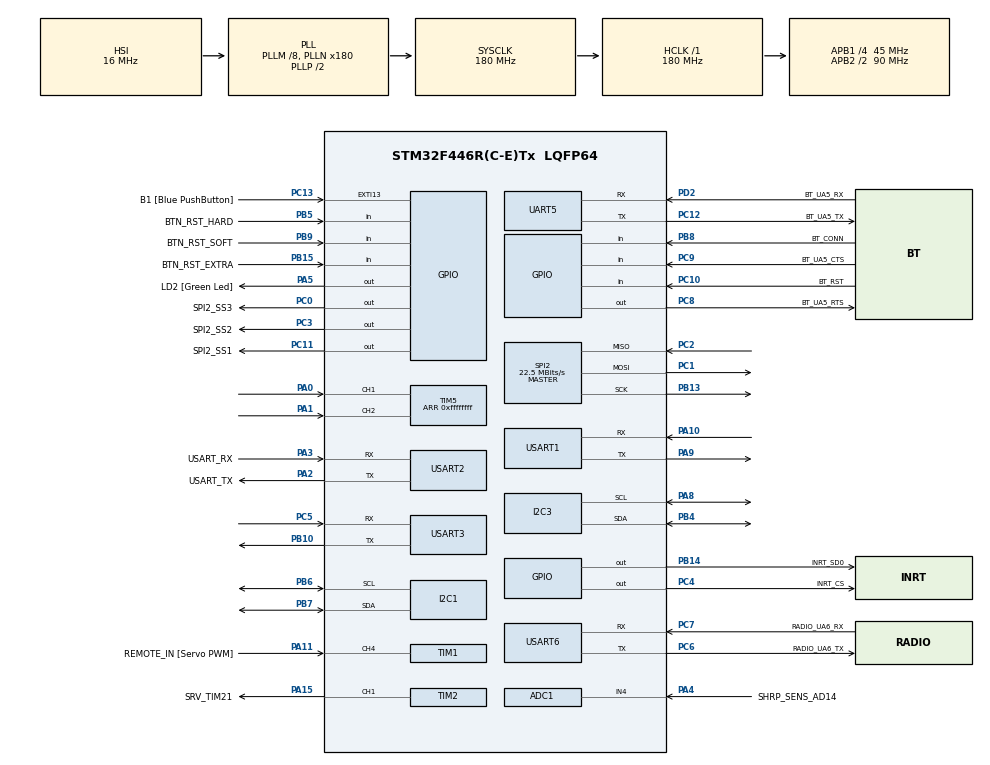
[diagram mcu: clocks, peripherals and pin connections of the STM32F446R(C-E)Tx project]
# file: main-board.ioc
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ADC1.Channel-4\#ChannelRegularConversion=ADC_CHANNEL_4
ADC1.NbrOfConversionFlag=1
ADC1.Rank-4\#ChannelRegularConversion=1
ADC1.SamplingTime-4\#ChannelRegularConversion=ADC_SAMPLETIME_3CYCLES
ADC1.master=1
FREERTOS.INCLUDE_uxTaskGetStackHighWaterMark=1
FREERTOS.Tasks01=defaultTask,0,128,StartDefaultTask,Default,NULL
FREERTOS.configCHECK_FOR_STACK_OVERFLOW=2
FREERTOS.configGENERATE_RUN_TIME_STATS=1
Mcu.Family=STM32F4
Mcu.Name=STM32F446R(C-E)Tx
Mcu.Package=LQFP64
NVIC.ADC_IRQn=true\:5\:0\:false\:false\:true\:true\:true
NVIC.I2C1_EV_IRQn=true\:5\:0\:false\:false\:true\:true\:true
NVIC.I2C3_EV_IRQn=true\:5\:0\:false\:false\:true\:true\:true
NVIC.PriorityGroup=NVIC_PRIORITYGROUP_4
NVIC.TIM1_CC_IRQn=true\:5\:0\:false\:false\:true\:true\:true
NVIC.TIM4_IRQn=true\:5\:0\:false\:false\:true\:true\:true
NVIC.TIM8_TRG_COM_TIM14_IRQn=true\:0\:0\:false\:false\:true\:false\:false
NVIC.TimeBase=TIM8_TRG_COM_TIM14_IRQn
NVIC.TimeBaseIP=TIM14
PA0-WKUP.Signal=S_TIM5_CH1
PA1.Signal=S_TIM5_CH2
PA10.Mode=Asynchronous
PA10.Signal=USART1_RX
PA11.GPIO_Label=REMOTE_IN [Servo PWM]
PA11.Signal=S_TIM1_CH4
PA13.GPIO_Label=TMS
PA13.Signal=SYS_JTMS-SWDIO
PA14.GPIO_Label=TCK
PA14.Signal=SYS_JTCK-SWCLK
PA15.GPIO_Label=SRV_TIM21
PA15.Signal=S_TIM2_CH1_ETR
PA2.GPIO_Label=USART_TX
PA2.Mode=Asynchronous
PA2.Signal=USART2_TX
PA3.GPIO_Label=USART_RX
PA3.Mode=Asynchronous
PA3.Signal=USART2_RX
PA4.GPIO_Label=SHRP_SENS_AD14
PA4.Signal=ADCx_IN4
PA5.GPIO_Label=LD2 [Green Led]
PA5.Signal=GPIO_Output
PA8.Mode=I2C
PA8.Signal=I2C3_SCL
PA9.Mode=Asynchronous
PA9.Signal=USART1_TX
PB10.Mode=Asynchronous
PB10.Signal=USART3_TX
PB13.Mode=Full_Duplex_Master
PB13.Signal=SPI2_SCK
PB14.GPIO_Label=INRT_SD0
PB14.Signal=GPIO_Output
PB15.GPIO_Label=BTN_RST_EXTRA
PB15.GPIO_PuPd=GPIO_PULLUP
PB15.Signal=GPIO_Input
PB3.GPIO_Label=SWO
PB3.Signal=SYS_JTDO-SWO
PB4.Mode=I2C
PB4.Signal=I2C3_SDA
PB5.GPIO_Label=BTN_RST_HARD
PB5.GPIO_PuPd=GPIO_PULLUP
PB5.Signal=GPIO_Input
PB6.Mode=I2C
PB6.Signal=I2C1_SCL
PB7.Mode=I2C
PB7.Signal=I2C1_SDA
PB8.GPIO_Label=BT_CONN
PB8.Signal=GPIO_Input
PB9.GPIO_Label=BTN_RST_SOFT
PB9.GPIO_PuPd=GPIO_PULLUP
PB9.Signal=GPIO_Input
PC0.GPIO_Label=SPI2_SS3
PC0.Signal=GPIO_Output
PC1.Mode=Full_Duplex_Master
PC1.Signal=SPI2_MOSI
PC10.GPIO_Label=BT_RST
PC10.Signal=GPIO_Input
PC11.GPIO_Label=SPI2_SS1
PC11.Signal=GPIO_Output
PC12.GPIO_Label=BT_UA5_TX
PC12.Mode=Asynchronous
PC12.Signal=UART5_TX
PC13.GPIO_Label=B1 [Blue PushButton]
PC13.GPIO_ModeDefaultEXTI=GPIO_MODE_IT_FALLING
PC13.Signal=GPXTI13
PC14-OSC32_IN.Signal=RCC_OSC32_IN
PC15-OSC32_OUT.Signal=RCC_OSC32_OUT
PC2.Mode=Full_Duplex_Master
PC2.Signal=SPI2_MISO
PC3.GPIO_Label=SPI2_SS2
PC3.Signal=GPIO_Output
PC4.GPIO_Label=INRT_CS
PC4.Signal=GPIO_Output
PC5.Mode=Asynchronous
PC5.Signal=USART3_RX
PC6.GPIO_Label=RADIO_UA6_TX
PC6.Mode=Asynchronous
PC6.Signal=USART6_TX
PC7.GPIO_Label=RADIO_UA6_RX
PC7.Mode=Asynchronous
PC7.Signal=USART6_RX
PC8.GPIO_Label=BT_UA5_RTS
PC8.Signal=GPIO_Output
PC9.GPIO_Label=BT_UA5_CTS
PC9.Signal=GPIO_Input
PD2.GPIO_Label=BT_UA5_RX
PD2.Mode=Asynchronous
PD2.Signal=UART5_RX
PH0-OSC_IN.Signal=RCC_OSC_IN
PH1-OSC_OUT.Signal=RCC_OSC_OUT
ProjectManager.HeapSize=0x200
ProjectManager.StackSize=0x400
ProjectManager.TargetToolchain=TrueSTUDIO
RCC.AHBFreq_Value=180000000
RCC.APB1CLKDivider=RCC_HCLK_DIV4
RCC.APB1Freq_Value=45000000
RCC.APB1TimFreq_Value=90000000
RCC.APB2CLKDivider=RCC_HCLK_DIV2
RCC.APB2Freq_Value=90000000
RCC.APB2TimFreq_Value=180000000
RCC.CortexFreq_Value=180000000
RCC.FLatency-AdvancedSettings=FLASH_LATENCY_5
RCC.HCLKFreq_Value=180000000
RCC.HSE_VALUE=8000000
RCC.HSI_VALUE=16000000
RCC.LSE_VALUE=32768
RCC.PLLM=8
RCC.PLLN=180
RCC.SYSCLKFreq_VALUE=180000000
RCC.SYSCLKSource=RCC_SYSCLKSOURCE_PLLCLK
RCC.USBFreq_Value=180000000
RCC.VCOOutputFreq_Value=360000000
SH.ADCx_IN4.0=ADC1_IN4,IN4
SH.S_TIM1_CH4.0=TIM1_CH4,Input_Capture4_from_TI4
SH.S_TIM2_CH1_ETR.0=TIM2_CH1,PWM Generation1 CH1
SH.S_TIM5_CH1.0=TIM5_CH1,Encoder_Interface
SH.S_TIM5_CH2.0=TIM5_CH2,Encoder_Interface
SPI2.BaudRatePrescaler=SPI_BAUDRATEPRESCALER_2
SPI2.CalculateBaudRate=22.5 MBits/s
SPI2.Direction=SPI_DIRECTION_2LINES
SPI2.Mode=SPI_MODE_MASTER
SPI2.VirtualType=VM_MASTER
TIM1.Channel-Input_Capture4_from_TI4=TIM_CHANNEL_4
TIM1.ICFilter_CH4=15
TIM1.ICPolarity_CH4=TIM_INPUTCHANNELPOLARITY_BOTHEDGE
TIM1.Period=0xffff
TIM1.Prescaler=90-1
TIM2.Channel-PWM\ Generation1\ CH1=TIM_CHANNEL_1
TIM2.CounterMode=TIM_COUNTERMODE_UP
TIM2.Period=0
TIM2.TIM_MasterOutputTrigger=TIM_TRGO_RESET
TIM4.Channel-Output\ Compare1\ No\ Output=TIM_CHANNEL_1
TIM4.Period=1000-1
TIM4.Prescaler=90-1
TIM5.EncoderMode=TIM_ENCODERMODE_TI12
TIM5.Period=0xffffffff
UART5.VirtualMode=Asynchronous
USART1.VirtualMode=VM_ASYNC
USART2.VirtualMode=VM_ASYNC
USART3.VirtualMode=VM_ASYNC
USART6.VirtualMode=VM_ASYNC
VP_FREERTOS_VS_ENABLE.Mode=Enabled
VP_SYS_VS_tim14.Mode=TIM14
VP_TIM1_VS_ClockSourceINT.Mode=Internal
VP_TIM4_VS_no_output1.Mode=Output Compare1 No Output
board=NUCLEO-F446RE

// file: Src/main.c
/* USER CODE BEGIN Header */
/**
  ******************************************************************************
  * @file           : main.c
  * @brief          : Main program body
  ******************************************************************************
  * This notice applies to any and all portions of this file
  * that are not between comment pairs USER CODE BEGIN and
  * USER CODE END. Other portions of this file, whether
  * inserted by the user or by software development tools
  * are owned by their respective copyright owners.
  *
  * Copyright (c) 2019 STMicroelectronics International N.V.
  * All rights reserved.
  *
  * Redistribution and use in source and binary forms, with or without
  * modification, are permitted, provided that the following conditions are met:
  *
  * 1. Redistribution of source code must retain the above copyright notice,
  *    this list of conditions and the following disclaimer.
  * 2. Redistributions in binary form must reproduce the above copyright notice,
  *    this list of conditions and the following disclaimer in the documentation
  *    and/or other materials provided with the distribution.
  * 3. Neither the name of STMicroelectronics nor the names of other
  *    contributors to this software may be used to endorse or promote products
  *    derived from this software without specific written permission.
  * 4. This software, including modifications and/or derivative works of this
  *    software, must execute solely and exclusively on microcontroller or
  *    microprocessor devices manufactured by or for STMicroelectronics.
  * 5. Redistribution and use of this software other than as permitted under
  *    this license is void and will automatically terminate your rights under
  *    this license.
  *
  * THIS SOFTWARE IS PROVIDED BY STMICROELECTRONICS AND CONTRIBUTORS "AS IS"
  * AND ANY EXPRESS, IMPLIED OR STATUTORY WARRANTIES, INCLUDING, BUT NOT
  * LIMITED TO, THE IMPLIED WARRANTIES OF MERCHANTABILITY, FITNESS FOR A
  * PARTICULAR PURPOSE AND NON-INFRINGEMENT OF THIRD PARTY INTELLECTUAL PROPERTY
  * RIGHTS ARE DISCLAIMED TO THE FULLEST EXTENT PERMITTED BY LAW. IN NO EVENT
  * SHALL STMICROELECTRONICS OR CONTRIBUTORS BE LIABLE FOR ANY DIRECT, INDIRECT,
  * INCIDENTAL, SPECIAL, EXEMPLARY, OR CONSEQUENTIAL DAMAGES (INCLUDING, BUT NOT
  * LIMITED TO, PROCUREMENT OF SUBSTITUTE GOODS OR SERVICES; LOSS OF USE, DATA,
  * OR PROFITS; OR BUSINESS INTERRUPTION) HOWEVER CAUSED AND ON ANY THEORY OF
  * LIABILITY, WHETHER IN CONTRACT, STRICT LIABILITY, OR TORT (INCLUDING
  * NEGLIGENCE OR OTHERWISE) ARISING IN ANY WAY OUT OF THE USE OF THIS SOFTWARE,
  * EVEN IF ADVISED OF THE POSSIBILITY OF SUCH DAMAGE.
  *
  ******************************************************************************
  */
/* USER CODE END Header */

#include "main.h"
#include "cmsis_os.h"
#include "adc.h"
#include "i2c.h"
#include "spi.h"
#include "tim.h"
#include "usart.h"
#include "gpio.h"

/* USER CODE BEGIN Includes */
#include "app_init.h"

#include "speed.h" /* Bc of that damn periodelapsedcallback */
/* USER CODE END Includes */

/* USER CODE BEGIN PV */
/* Private variables ---------------------------------------------------------*/

/* USER CODE END PV */

void SystemClock_Config(void);
void MX_FREERTOS_Init(void);
/* USER CODE BEGIN PFP */
/* Private function prototypes -----------------------------------------------*/

/* USER CODE END PFP */

int main(void)
{

  /* MCU Configuration--------------------------------------------------------*/

  /* Reset of all peripherals, Initializes the Flash interface and the Systick. */

	HAL_Init();

  /* Configure the system clock */
  SystemClock_Config();

  /* Initialize all configured peripherals */
  MX_GPIO_Init();
  MX_USART6_UART_Init();
  MX_USART3_UART_Init();
  MX_USART2_UART_Init();
  MX_USART1_UART_Init();
  MX_ADC1_Init();
  MX_TIM2_Init();
  MX_UART5_Init();
  MX_I2C1_Init();
  MX_SPI2_Init();
  MX_I2C3_Init();
  MX_TIM1_Init();
  MX_TIM4_Init();
  MX_TIM5_Init();
  /* USER CODE BEGIN 2 */
  Init();
  /* USER CODE END 2 */

  /* Call init function for freertos objects (in freertos.c) */
  MX_FREERTOS_Init();

  /* Start scheduler */
  osKernelStart();

  /* We should never get here as control is now taken by the scheduler */

  /* Infinite loop */
  while (1)
  {

  }
}

void SystemClock_Config(void)
{
  RCC_OscInitTypeDef RCC_OscInitStruct = {0};
  RCC_ClkInitTypeDef RCC_ClkInitStruct = {0};

  /**Configure the main internal regulator output voltage
  */
  __HAL_RCC_PWR_CLK_ENABLE();
  __HAL_PWR_VOLTAGESCALING_CONFIG(PWR_REGULATOR_VOLTAGE_SCALE1);
  /**Initializes the CPU, AHB and APB busses clocks
  */
  RCC_OscInitStruct.OscillatorType = RCC_OSCILLATORTYPE_HSI;
  RCC_OscInitStruct.HSIState = RCC_HSI_ON;
  RCC_OscInitStruct.HSICalibrationValue = RCC_HSICALIBRATION_DEFAULT;
  RCC_OscInitStruct.PLL.PLLState = RCC_PLL_ON;
  RCC_OscInitStruct.PLL.PLLSource = RCC_PLLSOURCE_HSI;
  RCC_OscInitStruct.PLL.PLLM = 8;
  RCC_OscInitStruct.PLL.PLLN = 180;
  RCC_OscInitStruct.PLL.PLLP = RCC_PLLP_DIV2;
  RCC_OscInitStruct.PLL.PLLQ = 2;
  RCC_OscInitStruct.PLL.PLLR = 2;
  if (HAL_RCC_OscConfig(&RCC_OscInitStruct) != HAL_OK)
  {
    Error_Handler();
  }
  /**Activate the Over-Drive mode
  */
  if (HAL_PWREx_EnableOverDrive() != HAL_OK)
  {
    Error_Handler();
  }
  /**Initializes the CPU, AHB and APB busses clocks
  */
  RCC_ClkInitStruct.ClockType = RCC_CLOCKTYPE_HCLK|RCC_CLOCKTYPE_SYSCLK
                              |RCC_CLOCKTYPE_PCLK1|RCC_CLOCKTYPE_PCLK2;
  RCC_ClkInitStruct.SYSCLKSource = RCC_SYSCLKSOURCE_PLLCLK;
  RCC_ClkInitStruct.AHBCLKDivider = RCC_SYSCLK_DIV1;
  RCC_ClkInitStruct.APB1CLKDivider = RCC_HCLK_DIV4;
  RCC_ClkInitStruct.APB2CLKDivider = RCC_HCLK_DIV2;

  if (HAL_RCC_ClockConfig(&RCC_ClkInitStruct, FLASH_LATENCY_5) != HAL_OK)
  {
    Error_Handler();
  }
}

void HAL_TIM_PeriodElapsedCallback(TIM_HandleTypeDef *htim)
{
  if (htim->Instance == TIM14) {
    HAL_IncTick();
  }
  /* USER CODE BEGIN Callback 1 */
  else if (htim->Instance == TIM4)
  {
	 speedCallback();
  }

  /* USER CODE END Callback 1 */
}

void Error_Handler(void)
{
  while(1)
  {
  }
}

/************************ (C) COPYRIGHT STMicroelectronics *****END OF FILE****/

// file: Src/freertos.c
/* USER CODE BEGIN Header */
/**
  ******************************************************************************
  * File Name          : freertos.c
  * Description        : Code for freertos applications
  ******************************************************************************
  * This notice applies to any and all portions of this file
  * that are not between comment pairs USER CODE BEGIN and
  * USER CODE END. Other portions of this file, whether
  * inserted by the user or by software development tools
  * are owned by their respective copyright owners.
  *
  * Copyright (c) 2018 STMicroelectronics International N.V.
  * All rights reserved.
  *
  * Redistribution and use in source and binary forms, with or without
  * modification, are permitted, provided that the following conditions are met:
  *
  * 1. Redistribution of source code must retain the above copyright notice,
  *    this list of conditions and the following disclaimer.
  * 2. Redistributions in binary form must reproduce the above copyright notice,
  *    this list of conditions and the following disclaimer in the documentation
  *    and/or other materials provided with the distribution.
  * 3. Neither the name of STMicroelectronics nor the names of other
  *    contributors to this software may be used to endorse or promote products
  *    derived from this software without specific written permission.
  * 4. This software, including modifications and/or derivative works of this
  *    software, must execute solely and exclusively on microcontroller or
  *    microprocessor devices manufactured by or for STMicroelectronics.
  * 5. Redistribution and use of this software other than as permitted under
  *    this license is void and will automatically terminate your rights under
  *    this license.
  *
  * THIS SOFTWARE IS PROVIDED BY STMICROELECTRONICS AND CONTRIBUTORS "AS IS"
  * AND ANY EXPRESS, IMPLIED OR STATUTORY WARRANTIES, INCLUDING, BUT NOT
  * LIMITED TO, THE IMPLIED WARRANTIES OF MERCHANTABILITY, FITNESS FOR A
  * PARTICULAR PURPOSE AND NON-INFRINGEMENT OF THIRD PARTY INTELLECTUAL PROPERTY
  * RIGHTS ARE DISCLAIMED TO THE FULLEST EXTENT PERMITTED BY LAW. IN NO EVENT
  * SHALL STMICROELECTRONICS OR CONTRIBUTORS BE LIABLE FOR ANY DIRECT, INDIRECT,
  * INCIDENTAL, SPECIAL, EXEMPLARY, OR CONSEQUENTIAL DAMAGES (INCLUDING, BUT NOT
  * LIMITED TO, PROCUREMENT OF SUBSTITUTE GOODS OR SERVICES; LOSS OF USE, DATA,
  * OR PROFITS; OR BUSINESS INTERRUPTION) HOWEVER CAUSED AND ON ANY THEORY OF
  * LIABILITY, WHETHER IN CONTRACT, STRICT LIABILITY, OR TORT (INCLUDING
  * NEGLIGENCE OR OTHERWISE) ARISING IN ANY WAY OUT OF THE USE OF THIS SOFTWARE,
  * EVEN IF ADVISED OF THE POSSIBILITY OF SUCH DAMAGE.
  *
  ******************************************************************************
  */
/* USER CODE END Header */

#include "FreeRTOS.h"
#include "task.h"
#include "main.h"
#include "cmsis_os.h"

osThreadId defaultTaskHandle;

void StartDefaultTask(void const * argument);

void MX_FREERTOS_Init(void); /* (MISRA C 2004 rule 8.1) */

/* Hook prototypes */
void configureTimerForRunTimeStats(void);
unsigned long getRunTimeCounterValue(void);
void vApplicationStackOverflowHook(xTaskHandle xTask, signed char *pcTaskName);

/* USER CODE BEGIN 1 */
/* Functions needed when configGENERATE_RUN_TIME_STATS is on */
__weak void configureTimerForRunTimeStats(void)
{

}

__weak unsigned long getRunTimeCounterValue(void)
{
return 0;
}
/* USER CODE END 1 */

/* USER CODE BEGIN 4 */
__weak void vApplicationStackOverflowHook(xTaskHandle xTask, signed char *pcTaskName)
{
   /* Run time stack overflow checking is performed if
   configCHECK_FOR_STACK_OVERFLOW is defined to 1 or 2. This hook function is
   called if a stack overflow is detected. */
}
/* USER CODE END 4 */

void MX_FREERTOS_Init(void) {

  /* Create the thread(s) */
  /* definition and creation of defaultTask */
  osThreadDef(defaultTask, StartDefaultTask, osPriorityNormal, 0, 128);
  defaultTaskHandle = osThreadCreate(osThread(defaultTask), NULL);

}

void StartDefaultTask(void const * argument)
{

  for(;;)
  {
    osDelay(1);
  }
}

/************************ (C) COPYRIGHT STMicroelectronics *****END OF FILE****/
